# PSC0 register map
Vendor: Texas Instruments
Peripheral module from a debugger description file (folder am65x).
Registers are 32-bit, read-only, reset values left out (the file's numbers can be read two ways) unless marked. A register's access mark holds for its fields unless they carry their own. Offsets are as the file gives them; lines under a group give offsets from that group; [hi:lo] are bit positions; {n}, {i} and the like mark numbered series; 'fields as' and 'values as' point back to an identical list; <NAME> marks a mode.

## PSC0
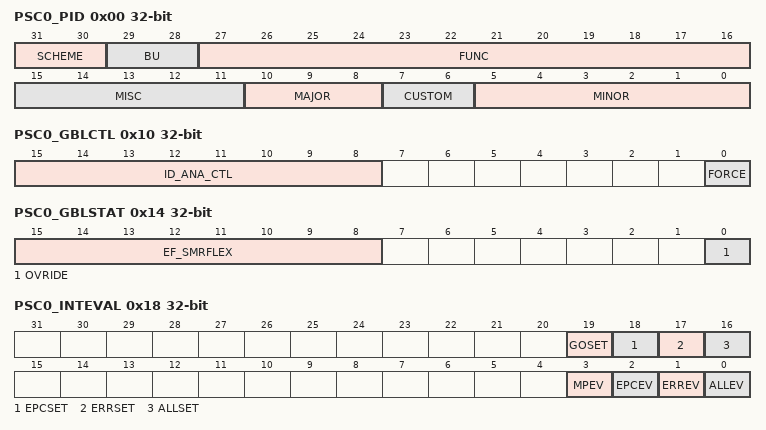
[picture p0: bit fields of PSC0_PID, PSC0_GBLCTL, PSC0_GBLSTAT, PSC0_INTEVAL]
0x00 PSC0_PID — Peripheral Identification Register This register is a constant register that contains the ID and ID revision number for that module. The stores version information used to identify the module.
  [31:30] SCHEME — Used to distinguish between old scheme and current.
  [29:28] BU
  [27:16] FUNC — Indicating a software compatible module family.
  [15:11] MISC
  [10:8] MAJOR — Major Revision.
  [7:6] CUSTOM — Indicates a Special Version for a particular device.
  [5:0] MINOR — Minor Revision.
0x10 PSC0_GBLCTL rw — Global Control Register Not supported. This register contains global control to PSC.
  [15:8] ID_ANA_CTL — Not supported.
  [0] FORCE — Force bit. Fer PSC 2.0, this bit is considered only if all of the conditions are true
0x14 PSC0_GBLSTAT rw — Global Status Register This register shows the PSC global status.
  [15:8] EF_SMRFLEX — Smart relfex class0 bits
  [0] OVRIDE — PSC Override Status
0x18 PSC0_INTEVAL rw — Interrupt Evaluation Register This register has no storage. Read from this register returns 0.
  [19] GOSET — GOSTAT Interrupt Set
  [18] EPCSET — External Power Control Interrupt Set
  [17] ERRSET — Error Interrupt Set
  [16] ALLSET — Combined Interrupt Set
  [3] MPEV — Re_evaluate Memory Protection Interrupt
  [2] EPCEV — External Power Control Interrupt
  [1] ERREV — Re-evaluate Error Interrupt
  [0] ALLEV — Re-evaluate Combined PSC Interrupt
0x40 PSC0_MERRPR0 — Module Error Pending Register 0 This register records pending error conditions for all modules. Each bit represents one module.
  [31:0] M — Module n Error Condition
0x44 PSC0_MERRPR1 — Module Error Pending Register 1 This register records pending error conditions for all modules. Each bit represents one module.
  [31:0] M — Module n Error Condition
0x50 PSC0_MERRCR0 rw — Module Error Clear Register 0 This register has no storage. Read from this register returns 0.
  [31:0] M — 0: Write of ‘0’ has no effect
0x54 PSC0_MERRCR1 rw — Module Error Clear Register 1 This register has no storage. Read from this register returns 0.
  [31:0] M — 0: Write of ‘0’ has no effect
0x60 PSC0_PERRPR — Power Error Pending Register This register records pending error conditions for each power domain. Each bit represents one domain.
  [31:0] P — Power Domain m Error Condition
0x68 PSC0_PERRCR rw — Power Error Clear Register This register has no storage. Read from this register returns 0.
  [31:0] P — 0: Write of ‘0’ has no effect
0x70 PSC0_EPCPR rw — External Power Control Pending Register This register records pending external power control conditions. Each bit represents one domain.
  [31:0] EPC — External Power Control Intervention Request for Power Domain n
0x78 PSC0_EPCCR rw — External Power Control Clear Register This register has no storage. Read from this register returns 0.
  [31:0] EPC — 0: Write of ‘0’ has no effect
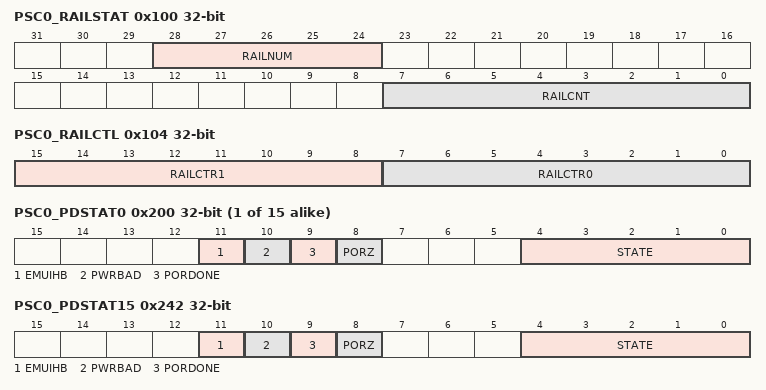
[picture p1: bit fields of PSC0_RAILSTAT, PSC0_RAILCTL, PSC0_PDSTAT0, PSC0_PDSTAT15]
0x100 PSC0_RAILSTAT — Power Rail Status Register This register is a read-only and shows the current rail requestor whose request is being granted and the current value of the counter associated with this requestor.
  [28:24] RAILNUM — Indicates Current Rail Requestor being processed by GPSC.
  [7:0] RAILCNT — Indicates the current rail counter value.
0x104 PSC0_RAILCTL rw — Power Rail Counter Control Register This register is user programmable. It holds the counter values for rail counter. User can select one of the two counter values to be used for each power domain (see RAILSEL register). This counter is clocked by gpsc_clk.
  [15:8] RAILCTR1 — Rail Counter Value 1
  [7:0] RAILCTR0 — Rail Counter Value 0
0x108 PSC0_RAILSEL rw — Power Rail Counter Select Register User can use this register to select the counter value(RAILCTL) for each power domain.
  [31:0] P — Rail Counter Select for Power Domain n
0x120 PSC0_PTCMD rw — Power Transition Command Register This is a pseudo-command register with no actual storage. Reads return 0. One bit for each power domain.
  [31:0] GO — Power Domain n GO Transition
0x120 PSC0_PTSTAT rw — Power Domain Transition Status Register This is a status register (read only).
  [31:0] GOSTAT — Power Domain n Transition Command Status
{0x200+4i} PSC0_PDSTAT{i} (i=0..14) — Power Domain Status Register {i} This is a status register (read only). It contains the status for power domain {i}.
  [11] EMUIHB — Emulation Alters Domain State Inhibits Off or Forces ON
  [10] PWRBAD — Power Bad Error.
  [9] PORDONE — POR Done Input Status
  [8] PORZ — PORz output actual status
  [4:0] STATE — Current Power Domain State.
0x242 PSC0_PDSTAT15 — Power Domain Status Register 15 This is a status register (read only). It contains the status for power domain 15.
  fields as PSC0_PDSTAT0
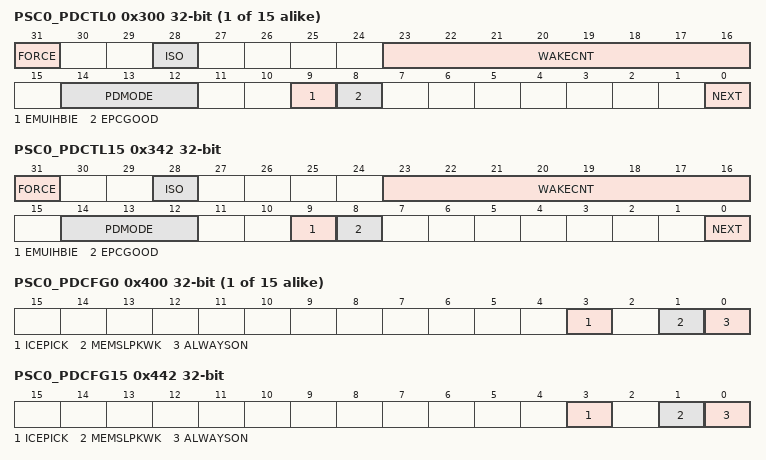
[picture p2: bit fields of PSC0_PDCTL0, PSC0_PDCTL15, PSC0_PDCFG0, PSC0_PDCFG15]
{0x300+4i} PSC0_PDCTL{i} rw (i=0..14) — Power Domain Control Register {i} This is a control register for power domain {i}.
  [31] FORCE — Force Bit.
  [28] ISO — Isolation Cell Control
  [23:16] WAKECNT — RAM wakecnt delay value.
  [14:12] PDMODE — Power Down mode
  [9] EMUIHBIE — Emulation Alters Domain State (Inhibits Domain Off or Forces Domain On) Interrupt Enable
  [8] EPCGOOD — External Power Control Power Good Indication.
  [0] NEXT — User-Desired Next Power Domain State.
0x342 PSC0_PDCTL15 rw — Power Domain Control Register 15 This is a control register for power domain 15.
  fields as PSC0_PDCTL0
{0x400+4i} PSC0_PDCFG{i} (i=0..14) — Power Domain Configuration Register {i} The PDCFG{i} register is a status register (read only). It shows PSC settings for easy debug.
  [3] ICEPICK — Icepick suuport
  [1] MEMSLPKWK — Memory sleep-wake domain
  [0] ALWAYSON — AlwaysON Power Domain
0x442 PSC0_PDCFG15 — Power Domain Configuration Register 15 The PDCFG15 register is a status register (read only). It shows PSC settings for easy debug.
  fields as PSC0_PDCFG0
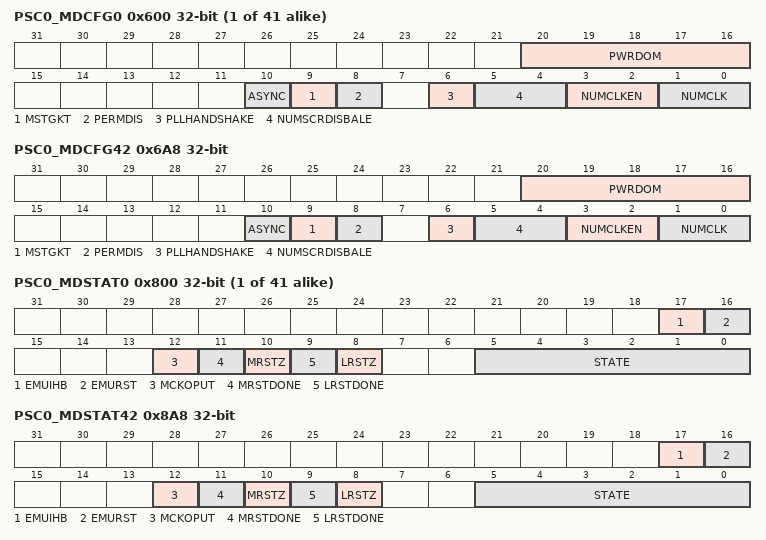
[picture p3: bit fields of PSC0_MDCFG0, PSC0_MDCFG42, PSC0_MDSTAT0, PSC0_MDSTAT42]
{0x600+4i} PSC0_MDCFG{i} (i=0..40) — Module Configuration Register {i} The MDCFG{i} register is a constant register showing some PSC settings for easy debug. This register is read only.
  [20:16] PWRDOM — Power Domain
  [10] ASYNC — Async Lpsc
  [9] MSTGKT — Master Gasket support
  [8] PERMDIS — Permanently Disable
  [6] PLLHANDSHAKE — RTL parameter PLL_HANDSHAKE
  [5:4] NUMSCRDISBALE — NUMBER OF POWER CLK disbale REQUIRED on LPSC
  [3:2] NUMCLKEN — NUMBER OF POWER CLK enable REQUIRED on LPSC
  [1:0] NUMCLK — Number of modclks supported on LPSC
0x6A8 PSC0_MDCFG42 — Module Configuration Register 42 The MDCFG42 register is a constant register showing some PSC settings for easy debug. This register is read only.
  fields as PSC0_MDCFG0
{0x800+4i} PSC0_MDSTAT{i} (i=0..40) — Module Status Register {i} The MDSTAT{i} register bit-fields show the status of each module. One register per module on the device.
  [17] EMUIHB — Emulation Alters Module State Inhibits Module Inactive or Force Module Active
  [16] EMURST — Emulation Alters Reset (lrst or mrst) to Module
  [12] MCKOPUT — Actual modclk output to module
  [11] MRSTDONE — Module reset initialization done status
  [10] MRSTZ — Module reset actual status
  [9] LRSTDONE — Module local reset initialization done status
  [8] LRSTZ — Module local reset actual status
  [5:0] STATE — These bits indicate the current module state.
0x8A8 PSC0_MDSTAT42 — Module Status Register 42 The MDSTAT42 register bit-fields show the status of each module. One register per module on the device.
  fields as PSC0_MDSTAT0
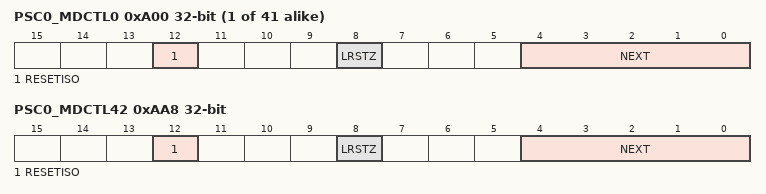
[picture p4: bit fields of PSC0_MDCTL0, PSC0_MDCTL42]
{0xA00+4i} PSC0_MDCTL{i} rw (i=0..40) — Module Control Register {i} The MDCTL{i} register provides specific control for the individual module. One register per module on the device.
  [12] RESETISO — Reset Isolation.
  [8] LRSTZ — Module local reset control (only applicable to some modules)
  [4:0] NEXT — Module Next State.
0xAA8 PSC0_MDCTL42 rw — Module Control Register 42 The MDCTL42 register provides specific control for the individual module. One register per module on the device.
  fields as PSC0_MDCTL0
